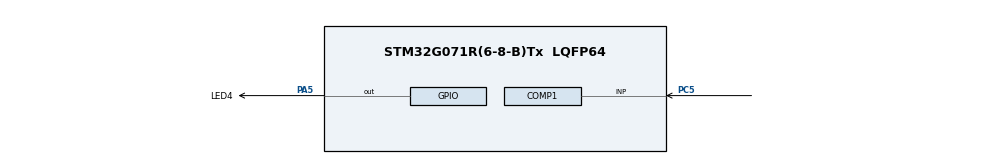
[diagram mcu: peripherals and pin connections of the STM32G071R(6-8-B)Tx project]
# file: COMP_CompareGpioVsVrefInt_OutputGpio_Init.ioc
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COMP1.Mode=COMP_POWERMODE_MEDIUMSPEED
Mcu.Family=STM32G0
Mcu.Name=STM32G071R(6-8-B)Tx
Mcu.Package=LQFP64
PA5.GPIO_Label=LED4
PA5.Signal=GPIO_Output
PC5.Mode=INP
PC5.Signal=COMP1_INP
ProjectManager.HeapSize=0x200
ProjectManager.StackSize=0x400
ProjectManager.TargetToolchain=EWARM V8.50
RCC.ADCFreq_Value=16000000
RCC.AHBFreq_Value=16000000
RCC.CodegenConfigPeriph=false
RCC.CortexFreq_Value=16000000
RCC.EXTERNAL_CLOCK_VALUE=48000
RCC.HCLKFreq_Value=16000000
RCC.HSE_VALUE=8000000
RCC.HSI_VALUE=16000000
RCC.LSE_VALUE=32768
RCC.PLLM=RCC_PLLM_DIV4
RCC.PLLN=70
RCC.PLLP=RCC_PLLP_DIV10
RCC.PLLQ=RCC_PLLQ_DIV5
RCC.PLLR=RCC_PLLR_DIV5
RCC.SYSCLKFreq_VALUE=16000000
RCC.VCOOutputFreq_Value=280000000
VP_COMP1_VS_VREFINT.Mode=VREFINT
VP_SYS_VS_DBSignals.Mode=DisableDeadBatterySignals
board=custom

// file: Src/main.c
/* USER CODE BEGIN Header */
/**
  ******************************************************************************
  * @file    Examples_LL/COMP/COMP_CompareGpioVsVrefInt_OutputGpio_Init/Src/main.c
  * @author  MCD Application Team
  * @brief   This example shows how to use a comparator peripheral
  *          to compare a voltage level applied on a GPIO pin
  *          versus the internal voltage reference (VrefInt),
  *          comparator output is connected to a GPIO.
  *          This example is based on the STM32G0xx COMP LL API;
  *          Peripheral initialization done using LL unitary services functions.
  ******************************************************************************
  * @attention
  *
  * Copyright (c) 2018-2020 STMicroelectronics.
  * All rights reserved.
  *
  * This software is licensed under terms that can be found in the LICENSE file
  * in the root directory of this software component.
  * If no LICENSE file comes with this software, it is provided AS-IS.
  *
  ******************************************************************************
  */
/* USER CODE END Header */
#include "main.h"

void SystemClock_Config(void);
static void MX_GPIO_Init(void);
static void MX_COMP1_Init(void);
/* USER CODE BEGIN PFP */
void     LED_On(void);
void     LED_Off(void);

/* USER CODE END PFP */

int main(void)
{

  /* MCU Configuration--------------------------------------------------------*/

  /* Reset of all peripherals, Initializes the Flash interface and the Systick. */
  LL_APB2_GRP1_EnableClock(LL_APB2_GRP1_PERIPH_SYSCFG);
  LL_APB1_GRP1_EnableClock(LL_APB1_GRP1_PERIPH_PWR);

  /** Disable the internal Pull-Up in Dead Battery pins of UCPD peripheral
  */
  LL_SYSCFG_DisableDBATT(LL_SYSCFG_UCPD1_STROBE | LL_SYSCFG_UCPD2_STROBE);

  /* Configure the system clock */
  SystemClock_Config();

  /* Initialize all configured peripherals */
  MX_GPIO_Init();
  MX_COMP1_Init();
  /* USER CODE BEGIN 2 */
  /* Lock comparator instance */
  //LL_COMP_Lock(COMP1);

  /* USER CODE END 2 */

  /* Infinite loop */
  /* USER CODE BEGIN WHILE */
  while (1)
  {
    /* Set LED state in function of state of GPIO connected to                */
    /* comparator output.                                                     */
    /* Note: State of GPIO is monitored for the purpose of this example.      */
    /*       An alternate solution is to monitor directly comparator output   */
    /*       using function "LL_COMP_ReadOutputLevel()".                      */
    if (LL_GPIO_IsInputPinSet(GPIOB, LL_GPIO_PIN_0) != 0)
    {
      LED_On();
    }
    else
    {
      LED_Off();
    }
    /* USER CODE END WHILE */

  }
}

void SystemClock_Config(void)
{
  /* HSI configuration and activation */
  LL_RCC_HSI_Enable();
  while(LL_RCC_HSI_IsReady() != 1)
  {
  }

  /* Set AHB prescaler*/
  LL_RCC_SetAHBPrescaler(LL_RCC_SYSCLK_DIV_1);

  /* Sysclk activation on the HSI */
  LL_RCC_SetSysClkSource(LL_RCC_SYS_CLKSOURCE_HSI);
  while(LL_RCC_GetSysClkSource() != LL_RCC_SYS_CLKSOURCE_STATUS_HSI)
  {
  }

  /* Set APB1 prescaler*/
  LL_RCC_SetAPB1Prescaler(LL_RCC_APB1_DIV_1);
  LL_Init1msTick(16000000);
  /* Update CMSIS variable (which can be updated also through SystemCoreClockUpdate function) */
  LL_SetSystemCoreClock(16000000);
}

static void MX_COMP1_Init(void)
{

  LL_COMP_InitTypeDef COMP_InitStruct = {0};

  LL_GPIO_InitTypeDef GPIO_InitStruct = {0};

  LL_IOP_GRP1_EnableClock(LL_IOP_GRP1_PERIPH_GPIOC);
  /**COMP1 GPIO Configuration
  PC5   ------> COMP1_INP
  */
  GPIO_InitStruct.Pin = LL_GPIO_PIN_5;
  GPIO_InitStruct.Mode = LL_GPIO_MODE_ANALOG;
  GPIO_InitStruct.Pull = LL_GPIO_PULL_NO;
  LL_GPIO_Init(GPIOC, &GPIO_InitStruct);

  /* USER CODE BEGIN COMP1_Init 1 */
  /* Configure GPIO connected to the comparator output */
  /* Note: Other GPIO are available as comparator output,                     */
  /*       refer to device datasheet.                                         */
  /* Enable GPIO clock */
  LL_IOP_GRP1_EnableClock(LL_IOP_GRP1_PERIPH_GPIOB);

  /* Configure GPIO output type */
  LL_GPIO_SetPinOutputType(GPIOB, LL_GPIO_PIN_0, LL_GPIO_OUTPUT_PUSHPULL);

  /* Configure GPIO speed */
  LL_GPIO_SetPinSpeed(GPIOB, LL_GPIO_PIN_0, LL_GPIO_SPEED_FREQ_HIGH);

  /* Configure GPIO in alternate function mode to be used as COMP output */
  LL_GPIO_SetPinMode(GPIOB, LL_GPIO_PIN_0, LL_GPIO_MODE_ALTERNATE);
  LL_GPIO_SetAFPin_0_7(GPIOB, LL_GPIO_PIN_0, LL_GPIO_AF_7);

  /* USER CODE END COMP1_Init 1 */
  COMP_InitStruct.InputPlus = LL_COMP_INPUT_PLUS_IO1;
  COMP_InitStruct.InputMinus = LL_COMP_INPUT_MINUS_VREFINT;
  COMP_InitStruct.InputHysteresis = LL_COMP_HYSTERESIS_NONE;
  COMP_InitStruct.OutputPolarity = LL_COMP_OUTPUTPOL_NONINVERTED;
  COMP_InitStruct.OutputBlankingSource = LL_COMP_BLANKINGSRC_NONE;
  LL_COMP_Init(COMP1, &COMP_InitStruct);
  LL_COMP_SetPowerMode(COMP1, LL_COMP_POWERMODE_MEDIUMSPEED);
  LL_COMP_SetCommonWindowMode(__LL_COMP_COMMON_INSTANCE(COMP1), LL_COMP_WINDOWMODE_DISABLE);
  LL_COMP_SetCommonWindowOutput(__LL_COMP_COMMON_INSTANCE(COMP1), LL_COMP_WINDOWOUTPUT_EACH_COMP);

  /* Wait loop initialization and execution */
  /* Note: Variable divided by 2 to compensate partially CPU processing cycles */
  __IO uint32_t wait_loop_index = 0;
  wait_loop_index = (LL_COMP_DELAY_VOLTAGE_SCALER_STAB_US * (SystemCoreClock / (1000000 * 2)));
  while(wait_loop_index != 0)
  {
    wait_loop_index--;
  }
  LL_EXTI_DisableEvent_0_31(LL_EXTI_LINE_17);
  LL_EXTI_DisableIT_0_31(LL_EXTI_LINE_17);
  /* USER CODE BEGIN COMP1_Init 2 */

 /* Enable comparator */
  LL_COMP_Enable(COMP1);

  /* Delay for comparator startup time.                                       */
  /* Compute number of CPU cycles to wait for, from delay in us.              */
  /* Note: Variable divided by 2 to compensate partially                      */
  /*       CPU processing cycles (depends on compilation optimization).       */
  /* Note: If system core clock frequency is below 200kHz, wait time          */
  /*       is only a few CPU processing cycles.                               */
  wait_loop_index = ((LL_COMP_DELAY_STARTUP_US * (SystemCoreClock / (100000 * 2))) / 10);
  while(wait_loop_index != 0)
  {
    wait_loop_index--;
  }

  /* USER CODE END COMP1_Init 2 */

}

static void MX_GPIO_Init(void)
{
  LL_GPIO_InitTypeDef GPIO_InitStruct = {0};

  /* GPIO Ports Clock Enable */
  LL_IOP_GRP1_EnableClock(LL_IOP_GRP1_PERIPH_GPIOA);
  LL_IOP_GRP1_EnableClock(LL_IOP_GRP1_PERIPH_GPIOC);

  /**/
  LL_GPIO_ResetOutputPin(LED4_GPIO_Port, LED4_Pin);

  /**/
  GPIO_InitStruct.Pin = LED4_Pin;
  GPIO_InitStruct.Mode = LL_GPIO_MODE_OUTPUT;
  GPIO_InitStruct.Speed = LL_GPIO_SPEED_FREQ_LOW;
  GPIO_InitStruct.OutputType = LL_GPIO_OUTPUT_PUSHPULL;
  GPIO_InitStruct.Pull = LL_GPIO_PULL_NO;
  LL_GPIO_Init(LED4_GPIO_Port, &GPIO_InitStruct);

}

/* USER CODE BEGIN 4 */

/**
  * @brief  Turn-on LED4.
  * @param  None
  * @retval None
  */
void LED_On(void)
{
  /* Turn LED4 on */
  LL_GPIO_SetOutputPin(LED4_GPIO_Port, LED4_Pin);
}

/**
  * @brief  Turn-off LED4.
  * @param  None
  * @retval None
  */
void LED_Off(void)
{
  /* Turn LED4 off */
  LL_GPIO_ResetOutputPin(LED4_GPIO_Port, LED4_Pin);
}

/* USER CODE END 4 */

void Error_Handler(void)
{
}
